AUTOSAR XML (schema 314)
package /ComponentType
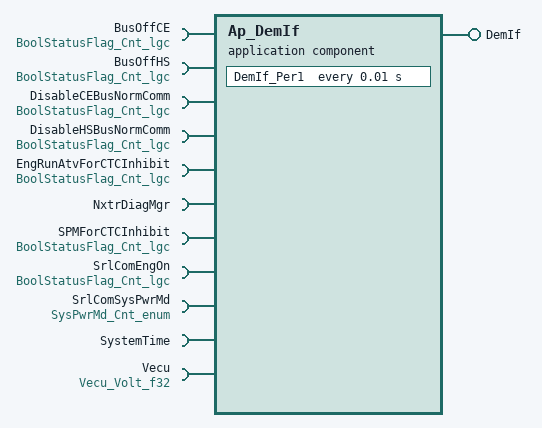
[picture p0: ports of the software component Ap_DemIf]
  application software component type Ap_DemIf
    provide port DemIf: provided-interface=DemIf
      provided-com-specs:
        operation=DemShutdown, queue-length=1
        operation=RestartDem, queue-length=1
        operation=SetEventStatus, queue-length=1
        operation=SetOperationCycleState, queue-length=1
    11 x require port:
      BusOffCE: unqueued-receiver-com-spec{data-element=Cnt_lgc, init-value=D_FALSE_CNT_LGC}, required-interface=BoolStatusFlag_Cnt_lgc
      BusOffHS: unqueued-receiver-com-spec{data-element=Cnt_lgc, init-value=D_FALSE_CNT_LGC}, required-interface=BoolStatusFlag_Cnt_lgc
      DisableCEBusNormComm: unqueued-receiver-com-spec{data-element=Cnt_lgc, init-value=D_FALSE_CNT_LGC}, required-interface=BoolStatusFlag_Cnt_lgc
      DisableHSBusNormComm: unqueued-receiver-com-spec{data-element=Cnt_lgc, init-value=D_FALSE_CNT_LGC}, required-interface=BoolStatusFlag_Cnt_lgc
      EngRunAtvForCTCInhibit: unqueued-receiver-com-spec{data-element=Cnt_lgc, init-value=D_FALSE_CNT_LGC}, required-interface=BoolStatusFlag_Cnt_lgc
      NxtrDiagMgr: required-com-specs=[GetNTCActive, GetNTCFailed, GetNTCStatus, SetNTCStatus], required-interface=NxtrDiagMgr
      SPMForCTCInhibit: unqueued-receiver-com-spec{data-element=Cnt_lgc, init-value=D_FALSE_CNT_LGC}, required-interface=BoolStatusFlag_Cnt_lgc
      SrlComEngOn: unqueued-receiver-com-spec{data-element=Cnt_lgc, init-value=D_FALSE_CNT_LGC}, required-interface=BoolStatusFlag_Cnt_lgc
      SrlComSysPwrMd: unqueued-receiver-com-spec{data-element=Cnt_enum, init-value=D_SYSPWRMODESTATEINIT_CNT_ENUM}, required-interface=SysPwrMd_Cnt_enum
      SystemTime: required-interface=SystemTime
        required-com-specs:
          DtrmnElapsedTime_mS_u16
          DtrmnElapsedTime_mS_u32
          DtrmnElapsedTime_uS_u16
          DtrmnElapsedTime_uS_u32
          GetSystemTime_mS_u32
          GetSystemTime_uS_u32
      Vecu: unqueued-receiver-com-spec{data-element=Volt_f32, init-value=D_VECUMIN_VOLTS_F32}, required-interface=Vecu_Volt_f32
  internal behavior Ap_DemIf_InternalBehavior: component=Ap_DemIf
    operation invoked event OIT_DemIf_DemShutdown_DemIf_DemShutdown: start-on-event=DemIf_DemShutdown, operation=DemIf.DemShutdown
    timing event TMT_DemIf_Per1: start-on-event=DemIf_Per1, period=0.01
    operation invoked event OIT_DemIf_RestartDem_DemIf_RestartDem: start-on-event=DemIf_RestartDem, operation=DemIf.RestartDem
    operation invoked event OIT_DemIf_SetEventStatus_DemIf_SetEventStatus: start-on-event=DemIf_SetEventStatus, operation=DemIf.SetEventStatus
    operation invoked event OIT_DemIf_SetOperationCycleState_DemIf_SetOperationCycleState: start-on-event=DemIf_SetOperationCycleState, operation=DemIf.SetOperationCycleState
    port-api-options:
      enable-take-address=false, indirect-api=false, port=BusOffCE
      enable-take-address=false, indirect-api=false, port=BusOffHS
      enable-take-address=false, indirect-api=false, port=DemIf
      enable-take-address=false, indirect-api=false, port=DisableCEBusNormComm
      enable-take-address=false, indirect-api=false, port=DisableHSBusNormComm
      enable-take-address=false, indirect-api=false, port=EngRunAtvForCTCInhibit
      enable-take-address=false, indirect-api=false, port=NxtrDiagMgr
      enable-take-address=false, indirect-api=false, port=SPMForCTCInhibit
      enable-take-address=false, indirect-api=false, port=SrlComEngOn
      enable-take-address=false, indirect-api=false, port=SrlComSysPwrMd
      enable-take-address=false, indirect-api=false, port=SystemTime
      enable-take-address=false, indirect-api=false, port=Vecu
    5 x runnable:
      DemIf_DemShutdown
      DemIf_Per1
        data read access READ_SrlComEngOn_Cnt_lgc: data-element=SrlComEngOn.Cnt_lgc
        data receive point REC_SrlComSysPwrMd_Cnt_enum: data-element=SrlComSysPwrMd.Cnt_enum
        sync call SC_SystemTime_DtrmnElapsedTime_mS_u16: operation=SystemTime.DtrmnElapsedTime_mS_u16, timeout=0
        sync call SC_SystemTime_GetSystemTime_mS_u32: operation=SystemTime.GetSystemTime_mS_u32, timeout=0
      DemIf_RestartDem
      DemIf_SetEventStatus
        8 x data receive point:
          REC_BusOffCE_Cnt_lgc: data-element=BusOffCE.Cnt_lgc
          REC_BusOffHS_Cnt_lgc: data-element=BusOffHS.Cnt_lgc
          REC_DisableCEBusNormComm_Cnt_lgc: data-element=DisableCEBusNormComm.Cnt_lgc
          REC_DisableHSBusNormComm_Cnt_lgc: data-element=DisableHSBusNormComm.Cnt_lgc
          REC_EngRunAtvForCTCInhibit_Cnt_lgc: data-element=EngRunAtvForCTCInhibit.Cnt_lgc
          REC_SPMForCTCInhibit_Cnt_lgc: data-element=SPMForCTCInhibit.Cnt_lgc
          REC_SrlComSysPwrMd_Cnt_enum: data-element=SrlComSysPwrMd.Cnt_enum
          REC_Vecu_Volt_f32: data-element=Vecu.Volt_f32
        sync call SC_NxtrDiagMgr_GetNTCActive: operation=NxtrDiagMgr.GetNTCActive, timeout=0
        sync call SC_SystemTime_DtrmnElapsedTime_mS_u32: operation=SystemTime.DtrmnElapsedTime_mS_u32, timeout=0
        sync call SC_SystemTime_GetSystemTime_mS_u32: operation=SystemTime.GetSystemTime_mS_u32, timeout=0
      DemIf_SetOperationCycleState: can-be-invoked-concurrently=true
  swc implementation Ap_DemIf_Implementation: behavior=Ap_DemIf_InternalBehavior
    code-descriptors:
      code Code: type=SRC
